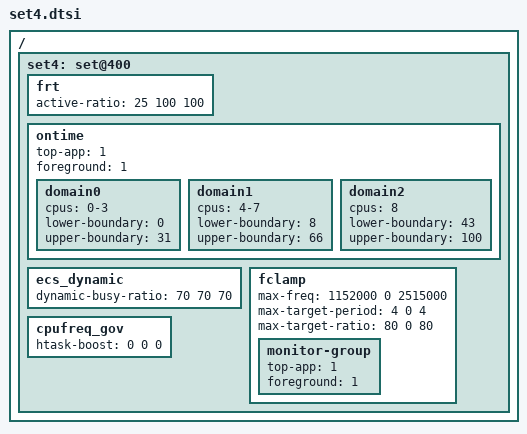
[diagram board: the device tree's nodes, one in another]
/ {
	/* balance mode - default */
	set4: set@400 {
		frt {	   	     		/* LIT MED BIG */
			active-ratio		= < 25 100 100>;
		};

		/* Ontime Migration */
		ontime {
			top-app		= <1>;
			foreground	= <1>;

			domain0 {
				cpus = "0-3";
				lower-boundary = <0>;
				upper-boundary = <31>;
			};
			domain1 {
				cpus = "4-7";
				lower-boundary = <8>;
				upper-boundary = <66>;
			};
			domain2 {
				cpus = "8";
				lower-boundary = <43>;
				upper-boundary = <100>;
			};
		};

		ecs_dynamic {
			dynamic-busy-ratio		= <70 70 70>;
		};

		fclamp {
			max-freq          = < 1152000       0 2515000>;
			max-target-period = <       4       0       4>;
			max-target-ratio  = <      80       0      80>;

			monitor-group {
				top-app         = <1>;
				foreground      = <1>;
			};
		};

		cpufreq_gov {
				/* LIT MED BIG */
			htask-boost = < 0 0 0 >;
		};
	};
};
